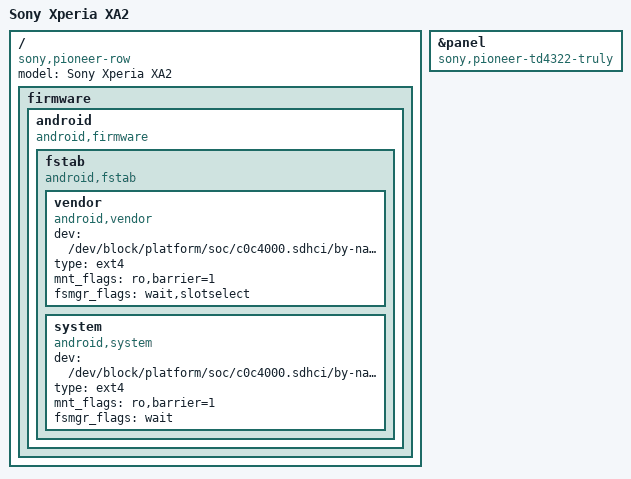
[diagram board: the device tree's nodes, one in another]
// SPDX-License-Identifier: BSD-3-Clause
/*
 * Copyright (c) 2020, Konrad Dybcio
 */

/dts-v1/;

#include "sdm630-sony-xperia-nile.dtsi"

/ {
	model = "Sony Xperia XA2";
	compatible = "sony,pioneer-row", "qcom,sdm630";

	firmware: firmware {
		android {
			compatible = "android,firmware";
			fstab {
				compatible = "android,fstab";

				vendor {
					compatible = "android,vendor";
					dev = "/dev/block/platform/soc/c0c4000.sdhci/by-name/vendor";
					type = "ext4";
					mnt_flags = "ro,barrier=1";
					fsmgr_flags = "wait,slotselect";
					status = "ok";
				};

				system {
					compatible = "android,system";
					dev = "/dev/block/platform/soc/c0c4000.sdhci/by-name/system_b";
					type = "ext4";
					mnt_flags = "ro,barrier=1";
					// WARNING: verity flag removed
					fsmgr_flags = "wait";
					status = "ok";
				};
			};
		};
	};
};

&panel {
	compatible = "sony,pioneer-td4322-truly";
};
